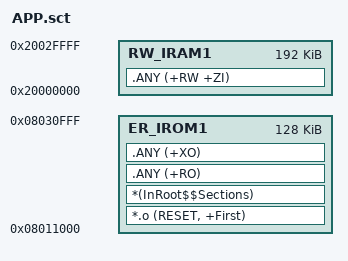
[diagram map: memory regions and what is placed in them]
; CIMC 2026 APP Scatter File
; Flash 地址: 0x08011000, 大小 128K (0x20000)
; 赛题 2.5 节规定: APP 区 0x08011000 ~ 0x08030FFF
;
; 注意: 初期调试可以把地址改回 0x08000000 0x80000 (512K)
;   Bootloader 跳转写好后再改回 0x08011000

LR_IROM1 0x08011000 0x20000  {

  ER_IROM1 0x08011000 0x20000  {
   *.o (RESET, +First)
   *(InRoot$$Sections)
   .ANY (+RO)
   .ANY (+XO)
  }

  RW_IRAM1 0x20000000 0x30000  {
   .ANY (+RW +ZI)
  }
}
